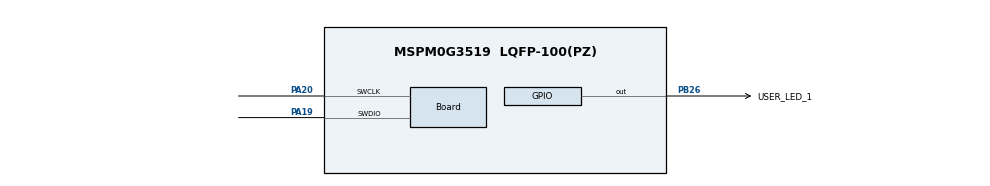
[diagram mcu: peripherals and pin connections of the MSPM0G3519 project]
//@cliArgs --device "MSPM0G351X" --package "LQFP-100(PZ)" --part "Default"
//@v2CliArgs --device "MSPM0G3519" --package "LQFP-100(PZ)"
// @cliArgs --board /ti/boards/LP_MSPM0G3519 --rtos nortos

/**
 * Import the modules used in this configuration.
 */
const ADC12  = scripting.addModule("/ti/driverlib/ADC12", {}, false);
const ADC121 = ADC12.addInstance();
const Board  = scripting.addModule("/ti/driverlib/Board");
const GPIO   = scripting.addModule("/ti/driverlib/GPIO", {}, false);
const GPIO1  = GPIO.addInstance();
const I2C    = scripting.addModule("/ti/driverlib/I2C", {}, false);
const I2C1   = I2C.addInstance();

/**
 * Write custom configuration values to the imported modules.
 */
ADC121.$name                      = "ADC12_0";
ADC121.enabledInterrupts          = ["DL_ADC12_INTERRUPT_MEM0_RESULT_LOADED"];
ADC121.powerDownMode              = "DL_ADC12_POWER_DOWN_MODE_MANUAL";
ADC121.sampClkDiv                 = "DL_ADC12_CLOCK_DIVIDE_8";
ADC121.sampleTime0                = "12.5 us";
ADC121.peripheral.$assign         = "ADC0";
ADC121.peripheral.adcPin0.$assign = "PA27";

Board.configureUnused             = true;
Board.peripheral.$assign          = "DEBUGSS";
Board.peripheral.swclkPin.$assign = "PA20";
Board.peripheral.swdioPin.$assign = "PA19";

GPIO1.$name                          = "GPIO_LEDS";
GPIO1.associatedPins[0].$name        = "USER_LED_1";
GPIO1.associatedPins[0].assignedPort = "PORTB";
GPIO1.associatedPins[0].assignedPin  = "26";
GPIO1.associatedPins[0].pin.$assign  = "PB26";

I2C1.basicControllerBusSpeed           = 400000;
I2C1.advControllerTXFIFOTRIG           = "BYTES_1";
I2C1.basicTargetAddress                = 0x48;
I2C1.$name                             = "I2C";
I2C1.basicEnableTarget                 = true;
I2C1.advTargetTXFIFOTRIG               = "BYTES_1";
I2C1.intTarget                         = ["RXFIFO_TRIGGER","START","STOP"];
I2C1.advAnalogGlitchFilter             = "DISABLED";
I2C1.advTargetTXEmptyEn                = true;

const SYSCTL                 = scripting.addModule("/ti/driverlib/SYSCTL", {}, false);
SYSCTL.clockTreeEn           = true;
SYSCTL.forceDefaultClkConfig = true;

const ProjectConfig              = scripting.addModule("/ti/project_config/ProjectConfig", {}, false);
ProjectConfig.migrationCondition = true;
